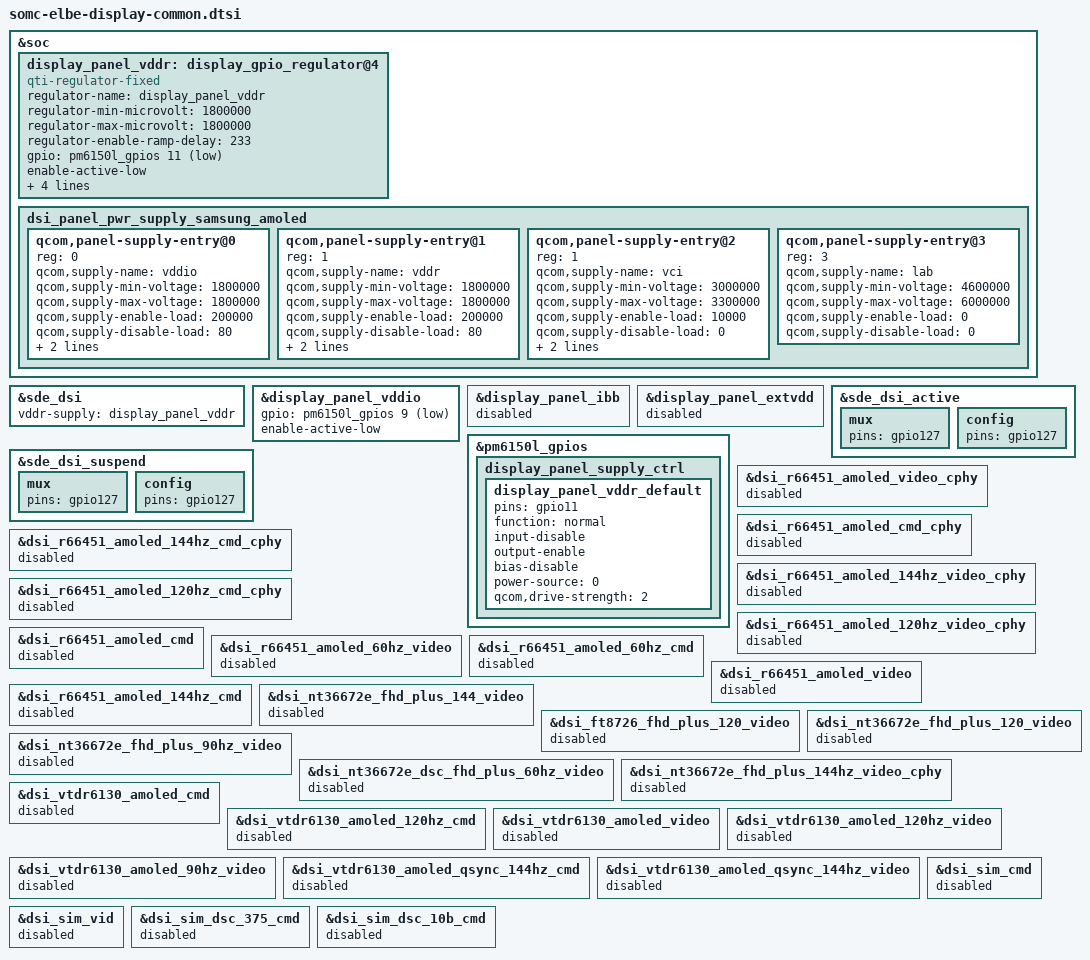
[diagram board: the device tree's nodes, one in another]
&soc {
	display_panel_vddr: display_gpio_regulator@4 {
		compatible = "qti-regulator-fixed";
		regulator-name = "display_panel_vddr";
		regulator-min-microvolt = <1800000>;
		regulator-max-microvolt = <1800000>;
		regulator-enable-ramp-delay = <233>;
		gpio = <&pm6150l_gpios 11 1>;
		enable-active-low;
		regulator-boot-on;
		proxy-supply = <&display_panel_vddr>;
		qcom,proxy-consumer-enable;
		pinctrl-names = "default";
		pinctrl-0 = <&display_panel_vddr_default>;
	};

	dsi_panel_pwr_supply_samsung_amoled: dsi_panel_pwr_supply_samsung_amoled {
		#address-cells = <1>;
		#size-cells = <0>;

		qcom,panel-supply-entry@0 {
			reg = <0>;
			qcom,supply-name = "vddio";
			qcom,supply-min-voltage = <1800000>;
			qcom,supply-max-voltage = <1800000>;
			qcom,supply-enable-load = <200000>;
			qcom,supply-disable-load = <80>;
			qcom,supply-post-on-sleep = <0>;
			qcom,supply-post-off-sleep = <10>;
		};

		qcom,panel-supply-entry@1 {
			reg = <1>;
			qcom,supply-name = "vddr";
			qcom,supply-min-voltage = <1800000>;
			qcom,supply-max-voltage = <1800000>;
			qcom,supply-enable-load = <200000>;
			qcom,supply-disable-load = <80>;
			qcom,supply-post-on-sleep = <20>;
			qcom,supply-post-off-sleep = <10>;
		};

		qcom,panel-supply-entry@2 {
			reg = <1>;
			qcom,supply-name = "vci";
			qcom,supply-min-voltage = <3000000>;
			qcom,supply-max-voltage = <3300000>;
			qcom,supply-enable-load = <10000>;
			qcom,supply-disable-load = <0>;
			qcom,supply-post-on-sleep = <25>;
			qcom,supply-post-off-sleep = <20>;
		};

		qcom,panel-supply-entry@3 {
			reg = <3>;
			qcom,supply-name = "lab";
			qcom,supply-min-voltage = <4600000>;
			qcom,supply-max-voltage = <6000000>;
			qcom,supply-enable-load = <0>;
			qcom,supply-disable-load = <0>;
		};
	};
};

&sde_dsi {
	/delete-property/ ibb-supply;
	/delete-property/ extvdd-supply;

	vddr-supply = <&display_panel_vddr>;
};

&display_panel_vddio {
	gpio = <&pm6150l_gpios 9 1>;
	enable-active-low;
};

&display_panel_ibb {
	status = "disabled";
};

&display_panel_extvdd {
	status = "disabled";
};

&pm6150l_gpios {
	display_panel_supply_ctrl {
		display_panel_vddr_default: display_panel_vddr_default {
			pins = "gpio11";
			function = "normal";
			input-disable;
			output-enable;
			bias-disable;
			power-source = <0>;
			qcom,drive-strength = <2>;
		};
	};
};

&sde_dsi_active {
	mux {
		pins = "gpio127";
	};

	config {
		pins = "gpio127";
	};
};

&sde_dsi_suspend {
	mux {
		pins = "gpio127";
	};

	config {
		pins = "gpio127";
	};
};

&dsi_r66451_amoled_video_cphy {
	status = "disabled";
};

&dsi_r66451_amoled_cmd_cphy {
	status = "disabled";
};

&dsi_r66451_amoled_144hz_cmd_cphy {
	status = "disabled";
};

&dsi_r66451_amoled_144hz_video_cphy {
	status = "disabled";
};

&dsi_r66451_amoled_120hz_cmd_cphy {
	status = "disabled";
};

&dsi_r66451_amoled_120hz_video_cphy {
	status = "disabled";
};

&dsi_r66451_amoled_cmd {
	status = "disabled";
};

&dsi_r66451_amoled_60hz_video {
	status = "disabled";
};

&dsi_r66451_amoled_60hz_cmd {
	status = "disabled";
};

&dsi_r66451_amoled_video {
	status = "disabled";
};

&dsi_r66451_amoled_144hz_cmd {
	status = "disabled";
};

&dsi_nt36672e_fhd_plus_144_video {
	status = "disabled";
};

&dsi_ft8726_fhd_plus_120_video {
	status = "disabled";
};

&dsi_nt36672e_fhd_plus_120_video {
	status = "disabled";
};

&dsi_nt36672e_fhd_plus_90hz_video {
	status = "disabled";
};

&dsi_nt36672e_dsc_fhd_plus_60hz_video {
	status = "disabled";
};

&dsi_nt36672e_fhd_plus_144hz_video_cphy {
	status = "disabled";
};

&dsi_vtdr6130_amoled_cmd {
	status = "disabled";
};

&dsi_vtdr6130_amoled_120hz_cmd {
	status = "disabled";
};

&dsi_vtdr6130_amoled_video {
	status = "disabled";
};

&dsi_vtdr6130_amoled_120hz_video {
	status = "disabled";
};

&dsi_vtdr6130_amoled_90hz_video {
	status = "disabled";
};

&dsi_vtdr6130_amoled_qsync_144hz_cmd {
	status = "disabled";
};

&dsi_vtdr6130_amoled_qsync_144hz_video {
	status = "disabled";
};

&dsi_sim_cmd {
	status = "disabled";
};

&dsi_sim_vid {
	status = "disabled";
};

&dsi_sim_dsc_375_cmd {
	status = "disabled";
};

&dsi_sim_dsc_10b_cmd {
	status = "disabled";
};
